# ing916 register map
Vendor: INGChips; Series: ing916xx; File version: 522
CPU: CM4 r0p1, little endian, MPU, FPU, VTOR, 5 interrupt priority bits
Registers are 32-bit, read-write, reset 0x0 unless marked. A register's access mark holds for its fields unless they carry their own. Offsets are from the block's base; [hi:lo] are bit positions; {n}, {i} and the like mark numbered series.

## I_CACHE_CTRL
Base 0x40140000
Same registers: D_CACHE_CTRL 0x40141000
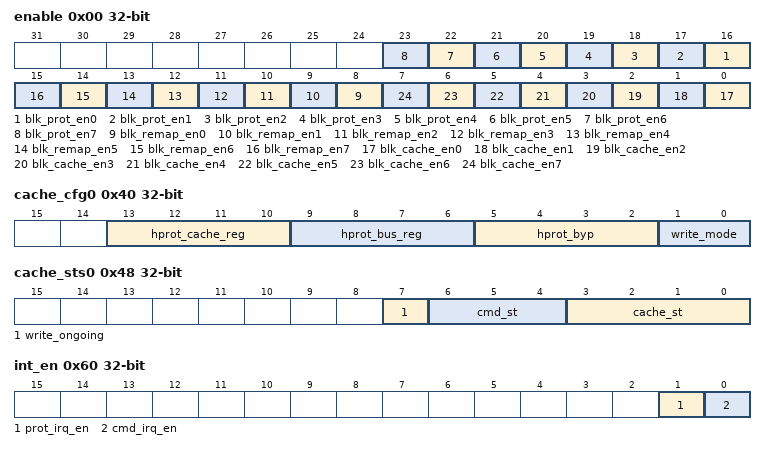
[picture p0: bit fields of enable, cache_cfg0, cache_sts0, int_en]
0x00 enable — reg description:
  [n+16] blk_prot_en{n} (n=0..7) — reg description:
  [n+8] blk_remap_en{n} (n=0..7) — reg description:
  [n] blk_cache_en{n} (n=0..7) — reg description:
{0x0+4i} base_addr{i} (i=1..7) — reg description:
{0x20+4i} remap{i} (i=0..7) — reg description:
0x40 cache_cfg0 — reg description:
  [13:10] hprot_cache_reg — reg description:
  [9:6] hprot_bus_reg — reg description:
  [5:2] hprot_byp — reg description:
  [1:0] write_mode — reg description:
0x44 bus_sts0 — reg description:
  [27:0] prot_detect_addr
0x48 cache_sts0 — reg description:
  [7] write_ongoing — reg description:
  [6:4] cmd_st — reg description:
  [3:0] cache_st — reg description:
0x50 cmd_cfg0 — reg description:
  [27:0] cmd_str_addr
0x54 cmd_cfg1 — reg description:
  [27:0] cmd_end_addr
0x58 cmd_cfg2 — reg description:
  [5:0] cmd_type
0x60 int_en — reg description:
  [1] prot_irq_en — reg description:
  [0] cmd_irq_en — reg description:
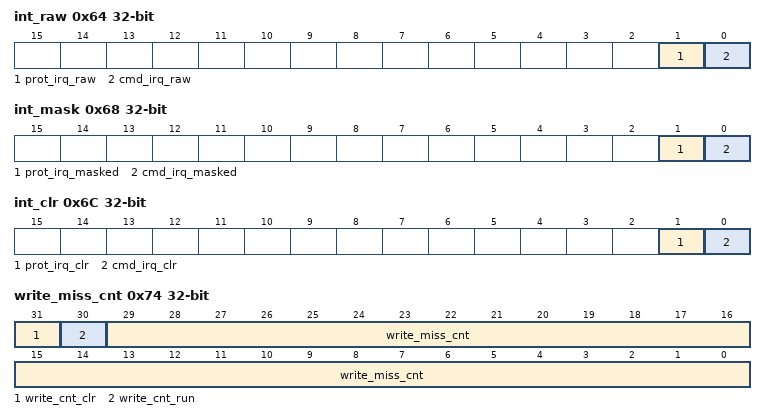
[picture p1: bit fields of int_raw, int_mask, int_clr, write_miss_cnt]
0x64 int_raw — reg description:
  [1] prot_irq_raw — reg description:
  [0] cmd_irq_raw — reg description:
0x68 int_mask — reg description:
  [1] prot_irq_masked — reg description:
  [0] cmd_irq_masked — reg description:
0x6C int_clr — reg description:
  [1] prot_irq_clr — reg description:
  [0] cmd_irq_clr — reg description:
0x70 write_hit_cnt — reg description:
0x74 write_miss_cnt — reg description:
  [31] write_cnt_clr — reg description:
  [30] write_cnt_run — reg description:
  [29:0] write_miss_cnt — reg description:
0x78 read_hit_cnt — reg description:
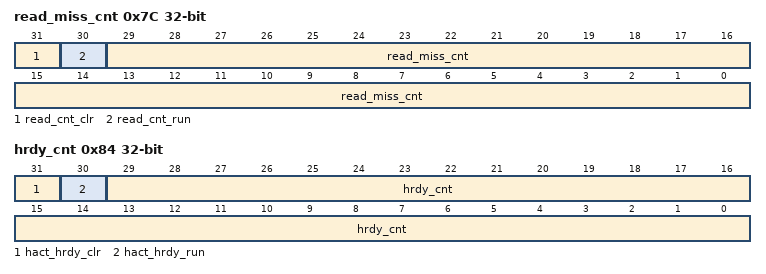
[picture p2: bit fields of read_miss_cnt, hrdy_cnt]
0x7C read_miss_cnt — reg description:
  [31] read_cnt_clr — reg description:
  [30] read_cnt_run — reg description:
  [29:0] read_miss_cnt — reg description:
0x80 hact_cnt — reg description:
0x84 hrdy_cnt — reg description:
  [31] hact_hrdy_clr — reg description:
  [30] hact_hrdy_run — reg description:
  [29:0] hrdy_cnt — reg description:

## FLASH_SPI_CTRL
Base 0x40150000
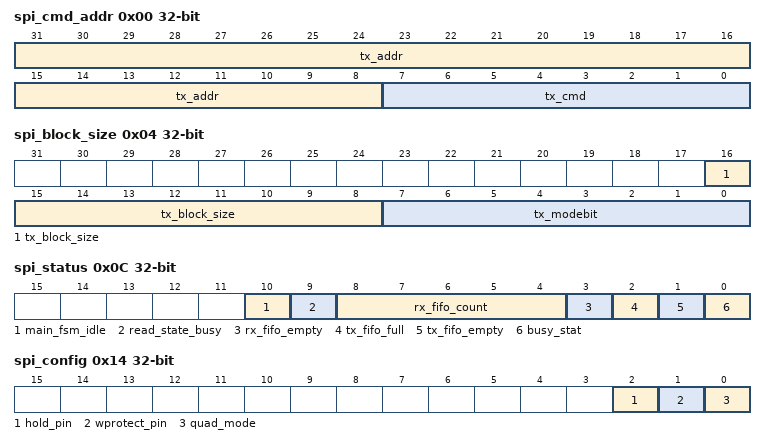
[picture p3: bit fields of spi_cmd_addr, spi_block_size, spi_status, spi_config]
0x00 spi_cmd_addr — reg description:
  [31:8] tx_addr — reg description:
  [7:0] tx_cmd — reg description:
0x04 spi_block_size — reg description:
  [16:8] tx_block_size — reg description:
  [7:0] tx_modebit — reg description:
0x08 spi_data_fifo — reg description:
0x0C spi_status — reg description:
  [10] main_fsm_idle — reg description:
  [9] read_state_busy — reg description:
  [8:4] rx_fifo_count — reg description:
  [3] rx_fifo_empty — reg description:
  [2] tx_fifo_full — reg description:
  [1] tx_fifo_empty — reg description:
  [0] busy_stat — reg description:
0x10 rx_status — reg description:
0x14 spi_config — reg description:
  [2] hold_pin — reg description:
  [1] wprotect_pin — reg description:
  [0] quad_mode — reg description:
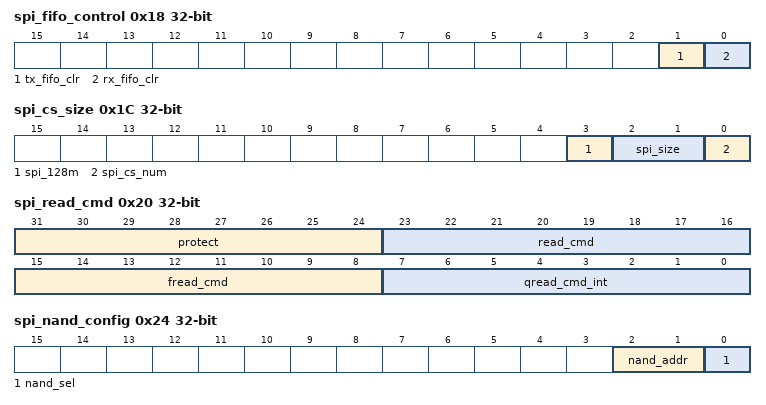
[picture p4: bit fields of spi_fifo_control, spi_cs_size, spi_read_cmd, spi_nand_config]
0x18 spi_fifo_control — reg description:
  [1] tx_fifo_clr — reg description:
  [0] rx_fifo_clr — reg description:
0x1C spi_cs_size — reg description:
  [3] spi_128m — reg description:
  [2:1] spi_size — reg description:
  [0] spi_cs_num — reg description:
0x20 spi_read_cmd — reg description:
  [31:24] protect — reg description:
  [23:16] read_cmd — reg description:
  [15:8] fread_cmd — reg description:
  [7:0] qread_cmd_int — reg description:
0x24 spi_nand_config — reg description:
  [2:1] nand_addr — reg description:
  [0] nand_sel — reg description:
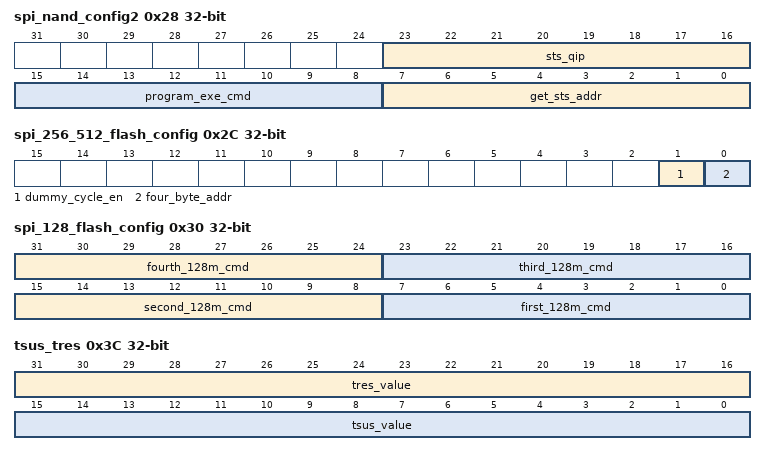
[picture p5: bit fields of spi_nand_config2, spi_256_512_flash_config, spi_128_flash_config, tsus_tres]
0x28 spi_nand_config2 — reg description:
  [23:16] sts_qip — reg description:
  [15:8] program_exe_cmd — reg description:
  [7:0] get_sts_addr — reg description:
0x2C spi_256_512_flash_config — reg description:
  [1] dummy_cycle_en — reg description:
  [0] four_byte_addr — reg description:
0x30 spi_128_flash_config — reg description:
  [31:24] fourth_128m_cmd — reg description:
  [23:16] third_128m_cmd — reg description:
  [15:8] second_128m_cmd — reg description:
  [7:0] first_128m_cmd — reg description:
0x34 timeout_value — reg description:
0x3C tsus_tres — reg description:
  [31:16] tres_value — reg description:
  [15:0] tsus_value — reg description:
0x40 flash_irq — reg description:
  [0] reg_irq
0x44 flash_irq_mask — reg description:
  [0] reg_irq_mask
